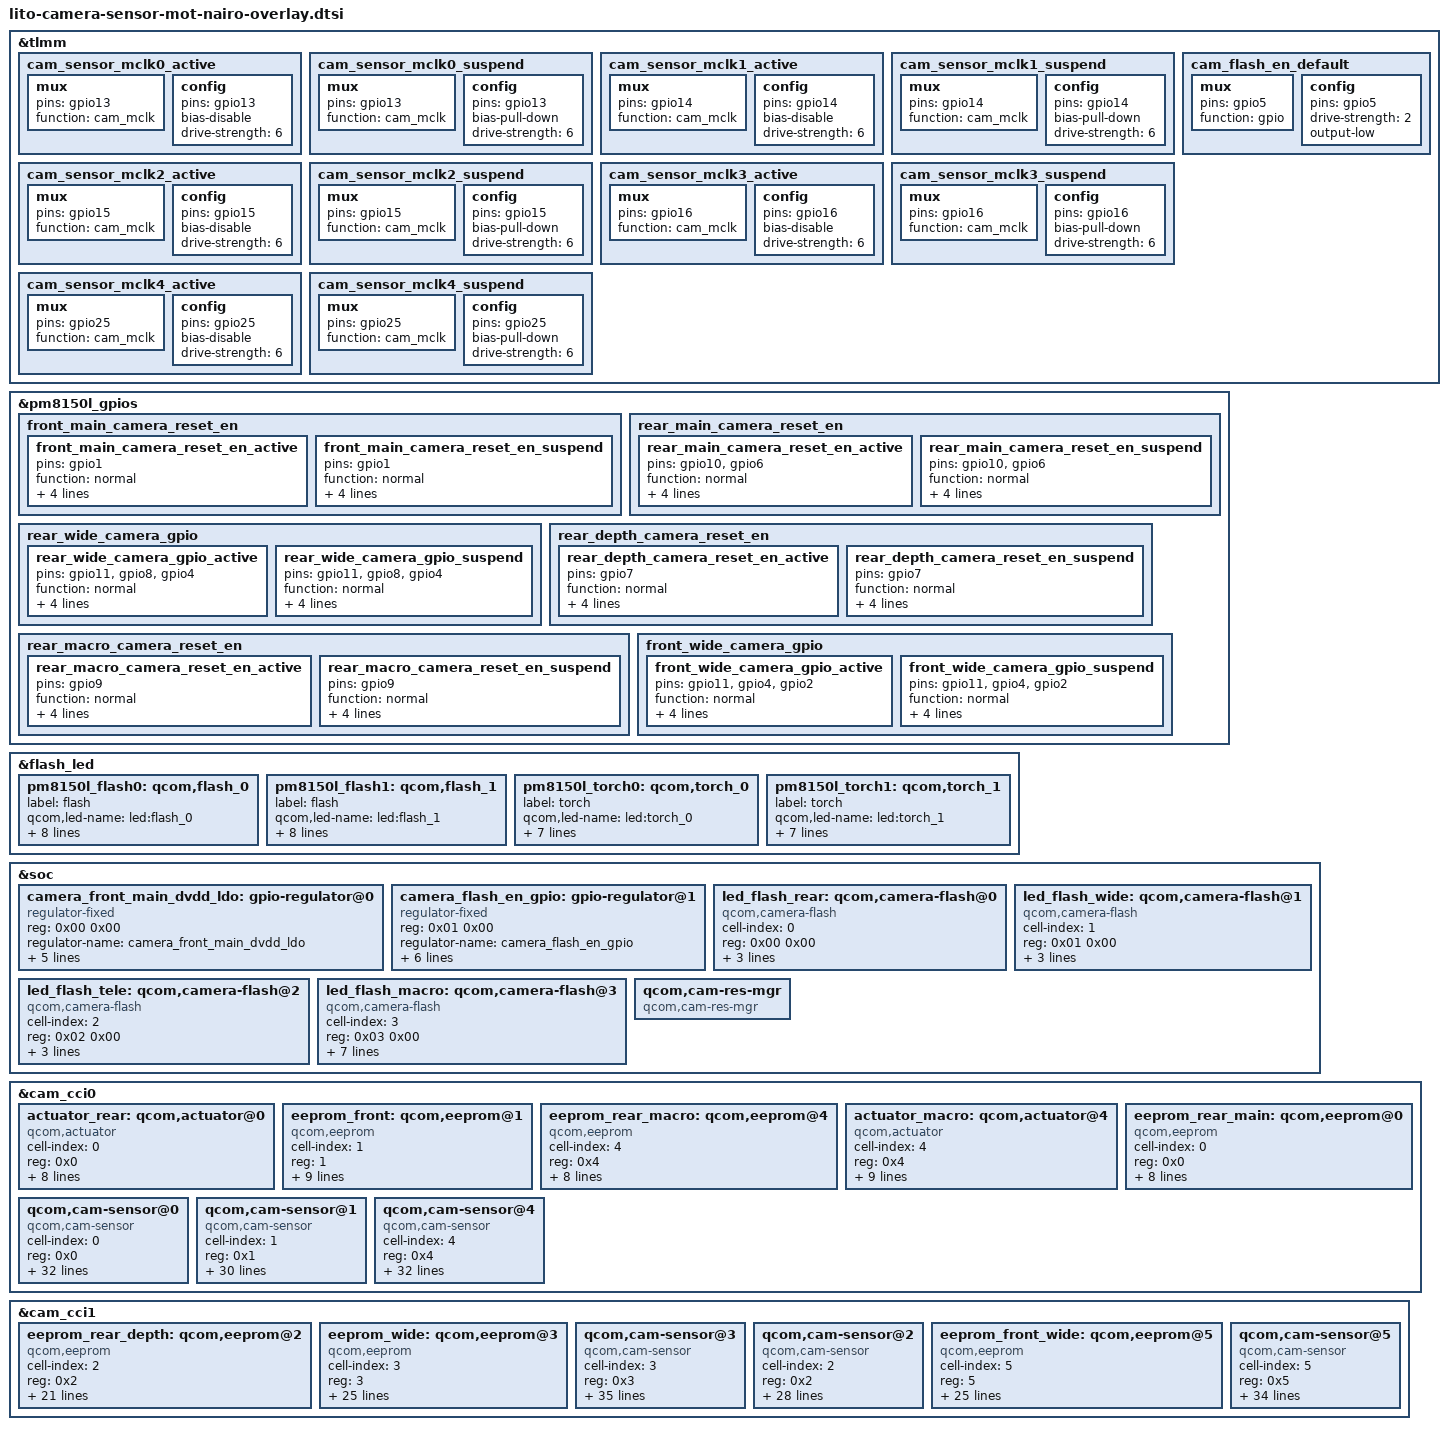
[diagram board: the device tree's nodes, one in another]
#include <dt-bindings/clock/qcom,camcc-lito.h>

&tlmm {
	cam_sensor_mclk0_active: cam_sensor_mclk0_active {
		/* MCLK0 */
		mux {
			pins = "gpio13";
			function = "cam_mclk";
		};

		config {
			pins = "gpio13";
			bias-disable; /* No PULL */
			drive-strength = <6>; /* 6 MA */
		};
	};

	cam_sensor_mclk0_suspend: cam_sensor_mclk0_suspend {
		/* MCLK0 */
		mux {
			pins = "gpio13";
			function = "cam_mclk";
		};

		config {
			pins = "gpio13";
			bias-pull-down; /* PULL DOWN */
			drive-strength = <6>; /* 6 MA */
		};
	};

	cam_sensor_mclk1_active: cam_sensor_mclk1_active {
		/* MCLK1 */
		mux {
			pins = "gpio14";
			function = "cam_mclk";
		};

		config {
			pins = "gpio14";
			bias-disable; /* No PULL */
			drive-strength = <6>; /* 6 MA */
		};
	};

	cam_sensor_mclk1_suspend: cam_sensor_mclk1_suspend {
		/* MCLK1 */
		mux {
			pins = "gpio14";
			function = "cam_mclk";
		};

		config {
			pins = "gpio14";
			bias-pull-down; /* PULL DOWN */
			drive-strength = <6>; /* 6 MA */
		};
	};

	cam_sensor_mclk2_active: cam_sensor_mclk2_active {
		/* MCLK2 */
		mux {
			pins = "gpio15";
			function = "cam_mclk";
		};

		config {
			pins = "gpio15";
			bias-disable; /* No PULL */
			drive-strength = <6>; /* 6 MA */
		};
	};

	cam_sensor_mclk2_suspend: cam_sensor_mclk2_suspend {
		/* MCLK2 */
		mux {
			pins = "gpio15";
			function = "cam_mclk";
		};

		config {
			pins = "gpio15";
			bias-pull-down; /* PULL DOWN */
			drive-strength = <6>; /* 6 MA */
		};
	};

	cam_sensor_mclk3_active: cam_sensor_mclk3_active {
		/* MCLK3 */
		mux {
			pins = "gpio16";
			function = "cam_mclk";
		};

		config {
			pins = "gpio16";
			bias-disable; /* No PULL */
			drive-strength = <6>; /* 6 MA */
		};
	};

	cam_sensor_mclk3_suspend: cam_sensor_mclk3_suspend {
		/* MCLK3 */
		mux {
			pins = "gpio16";
			function = "cam_mclk";
		};

		config {
			pins = "gpio16";
			bias-pull-down; /* PULL DOWN */
			drive-strength = <6>; /* 6 MA */
		};
	};

	cam_sensor_mclk4_active: cam_sensor_mclk4_active {
		/* MCLK4 */
		mux {
			pins = "gpio25";
			function = "cam_mclk";
		};

		config {
			pins = "gpio25";
			bias-disable; /* No PULL */
			drive-strength = <6>; /* 6 MA */
		};
	};

	cam_sensor_mclk4_suspend: cam_sensor_mclk4_suspend {
		/* MCLK4 */
		mux {
			pins = "gpio25";
			function = "cam_mclk";
		};

		config {
			pins = "gpio25";
			bias-pull-down; /* PULL DOWN */
			drive-strength = <6>; /* 6 MA */
		};
	};

	cam_flash_en_default: cam_flash_en_default {
		/* RESET */
		mux {
			pins = "gpio5";
			function = "gpio";
		};

		config{
			pins = "gpio5";
			drive-strength = <2>; /* 2 MA */
			output-low;
		};
	};
};
&pm8150l_gpios {
	front_main_camera_reset_en {
		front_main_camera_reset_en_active: front_main_camera_reset_en_active {
			pins = "gpio1";
			function = "normal";
			qcom,drive-strength = <2>;
			power-source = <0>;
			bias-disable;
			output-enable;
		};
		front_main_camera_reset_en_suspend: front_main_camera_reset_en_suspend {
			pins = "gpio1";
			function = "normal";
			qcom,drive-strength = <2>;
			power-source = <0>;
			bias-pull-down;
			output-low;
		};
	};
	/*       pmic gpio pins sequence：GPIO 7-11 in front, GPIO 1-6 in back    */
	rear_main_camera_reset_en {
		rear_main_camera_reset_en_active: rear_main_camera_reset_en_active {
			pins = "gpio10","gpio6";
			function = "normal";
			qcom,drive-strength = <2>;
			power-source = <1>;
			bias-disable;
			output-enable;
		};
		rear_main_camera_reset_en_suspend: rear_main_camera_reset_en_suspend {
			pins = "gpio10","gpio6";
			function = "normal";
			qcom,drive-strength = <2>;
			power-source = <1>;
			bias-pull-down;
			output-low;
		};
	};
	/*       pmic gpio pins sequence：GPIO 7-11 in front, GPIO 1-6 in back    */
	rear_wide_camera_gpio {
		rear_wide_camera_gpio_active: rear_wide_camera_gpio_active {
			pins = "gpio11","gpio8","gpio4";
			function = "normal";
			qcom,drive-strength = <2>;
			power-source = <1>;
			bias-disable;
			output-enable;
		};
		rear_wide_camera_gpio_suspend: rear_wide_camera_gpio_suspend {
			pins = "gpio11","gpio8","gpio4";
			function = "normal";
			qcom,drive-strength = <2>;
			power-source = <1>;
			bias-pull-down;
			output-low;
		};
	};

        rear_depth_camera_reset_en {
		rear_depth_camera_reset_en_active: rear_depth_camera_reset_en_active {
			pins = "gpio7";
			function = "normal";
			qcom,drive-strength = <2>;
                        power-source = <1>;
			bias-disable;
			output-enable;
			};
		rear_depth_camera_reset_en_suspend: rear_depth_camera_reset_en_suspend {
			pins = "gpio7";
			function = "normal";
			qcom,drive-strength = <2>;
			power-source = <1>;
			bias-pull-down;
			output-low;
		};
	};

	rear_macro_camera_reset_en {
		rear_macro_camera_reset_en_active: rear_macro_camera_reset_en_active {
			pins = "gpio9";
			function = "normal";
			qcom,drive-strength = <2>;
			power-source = <1>;
			bias-disable;
			output-enable;
			};
		rear_macro_camera_reset_en_suspend: rear_macro_camera_reset_en_suspend {
			pins = "gpio9";
			function = "normal";
			qcom,drive-strength = <2>;
			power-source = <1>;
			bias-pull-down;
			output-low;
		};
	};
	/*       pmic gpio pins sequence：GPIO 7-11 in front, GPIO 1-6 in back    */
	front_wide_camera_gpio {
		front_wide_camera_gpio_active: front_wide_camera_gpio_active {
			pins ="gpio11","gpio4","gpio2";
			function = "normal";
			qcom,drive-strength = <2>;
			power-source = <1>;
			bias-disable;
			output-enable;
		};
		front_wide_camera_gpio_suspend: front_wide_camera_gpio_suspend {
			pins ="gpio11","gpio4","gpio2";
			function = "normal";
			qcom,drive-strength = <2>;
			power-source = <1>;
			bias-pull-down;
			output-low;
		};
	};
};

&flash_led {
	pm8150l_flash0: qcom,flash_0 {
		label = "flash";
		qcom,led-name = "led:flash_0";
		qcom,max-current = <750>;
		qcom,default-led-trigger = "flash0_trigger";
		qcom,id = <0>;
		qcom,current-ma = <500>;
		qcom,duration-ms = <1280>;
		qcom,ires-ua = <12500>;
		qcom,hdrm-voltage-mv = <325>;
		qcom,hdrm-vol-hi-lo-win-mv = <100>;
	};

	pm8150l_flash1: qcom,flash_1 {
		label = "flash";
		qcom,led-name = "led:flash_1";
		qcom,max-current = <750>;
		qcom,default-led-trigger = "flash1_trigger";
		qcom,id = <1>;
		qcom,current-ma = <500>;
		qcom,duration-ms = <1280>;
		qcom,ires-ua = <12500>;
		qcom,hdrm-voltage-mv = <325>;
		qcom,hdrm-vol-hi-lo-win-mv = <100>;
	};

	pm8150l_torch0: qcom,torch_0 {
		label = "torch";
		qcom,led-name = "led:torch_0";
		qcom,max-current = <250>;
		qcom,default-led-trigger = "torch0_trigger";
		qcom,id = <0>;
		qcom,current-ma = <50>;
		qcom,ires-ua = <12500>;
		qcom,hdrm-voltage-mv = <325>;
		qcom,hdrm-vol-hi-lo-win-mv = <100>;
	};

	pm8150l_torch1: qcom,torch_1 {
		label = "torch";
		qcom,led-name = "led:torch_1";
		qcom,max-current = <250>;
		qcom,default-led-trigger = "torch1_trigger";
		qcom,id = <1>;
		qcom,current-ma = <50>;
		qcom,ires-ua = <12500>;
		qcom,hdrm-voltage-mv = <325>;
		qcom,hdrm-vol-hi-lo-win-mv = <100>;
	};
};

&soc {
	camera_front_main_dvdd_ldo: gpio-regulator@0 {
		compatible = "regulator-fixed";
		reg = <0x00 0x00>;
		regulator-name = "camera_front_main_dvdd_ldo";
		regulator-min-microvolt = <1200000>;
		regulator-max-microvolt = <1200000>;
		regulator-enable-ramp-delay = <135>;
		enable-active-high;
		gpio = <&pm8150l_gpios 10 0>;
	};

	camera_flash_en_gpio: gpio-regulator@1{
		compatible = "regulator-fixed";
		reg = <0x01 0x00>;
		regulator-name = "camera_flash_en_gpio";
		regulator-min-microvolt = <1800000>;
		regulator-max-microvolt = <1800000>;
		regulator-enable-ramp-delay = <233>;
		enable-active-high;
		gpio = <&tlmm 5 0>;
		pinctrl-names = "default";
		pinctrl-0 = <&cam_flash_en_default>;
	};

	led_flash_rear: qcom,camera-flash@0 {
		cell-index = <0>;
		reg = <0x00 0x00>;
		compatible = "qcom,camera-flash";
		flash-source = <&pm8150l_flash0 &pm8150l_flash1>;
		torch-source = <&pm8150l_torch0 &pm8150l_torch1>;
		switch-source = <&pm8150l_switch2>;
		status = "ok";
	};

	led_flash_wide: qcom,camera-flash@1 {
		cell-index = <1>;
		reg = <0x01 0x00>;
		compatible = "qcom,camera-flash";
		flash-source = <&pm8150l_flash0 &pm8150l_flash1>;
		torch-source = <&pm8150l_torch0 &pm8150l_torch1>;
		switch-source = <&pm8150l_switch2>;
		status = "ok";
	};

	led_flash_tele: qcom,camera-flash@2 {
		cell-index = <2>;
		reg = <0x02 0x00>;
		compatible = "qcom,camera-flash";
		flash-source = <&pm8150l_flash0 &pm8150l_flash1>;
		torch-source = <&pm8150l_torch0 &pm8150l_torch1>;
		switch-source = <&pm8150l_switch2>;
		status = "ok";
	};

	led_flash_macro: qcom,camera-flash@3 {
		cell-index = <3>;
		reg = <0x03 0x00>;
		compatible = "qcom,camera-flash";
		gpio-flash-support;
		cam_v_custom1-supply = <&camera_flash_en_gpio>;
		regulator-names = "cam_v_custom1";
		rgltr-cntrl-support;
		rgltr-min-voltage = <1800000>;
		rgltr-max-voltage = <1800000>;
		rgltr-load-current = <0>;
		status = "ok";
	};

	qcom,cam-res-mgr {
		compatible = "qcom,cam-res-mgr";
		status = "ok";
	};
};

&cam_cci0 {
	actuator_rear: qcom,actuator@0 {
		cell-index = <0>;
		reg = <0x0>;
		compatible = "qcom,actuator";
		cci-master = <0>;
		cam_vio-supply = <&cam_iovdd_ldo>;
		cam_vaf-supply = <&cam_main_macro_afvdd_ldo>;
		regulator-names = "cam_vio", "cam_vaf";
		rgltr-cntrl-support;
		rgltr-min-voltage = <1800000 2800000>;
		rgltr-max-voltage = <1800000 2800000>;
		rgltr-load-current = <0 100000>;
		status = "ok";
	};

	eeprom_front: qcom,eeprom@1 {
		cell-index = <1>;
		reg = <1>;
		compatible = "qcom,eeprom";
		cam_vio-supply = <&cam_iovdd_ldo>;
		regulator-names = "cam_vio";
		rgltr-cntrl-support;
		rgltr-min-voltage = <1800000>;
		rgltr-max-voltage = <1800000>;
		rgltr-load-current = <0>;
		sensor-mode = <1>;
		cci-device = <0>;
		cci-master = <1>;
		status = "ok";
	};

	eeprom_rear_macro: qcom,eeprom@4{
		cell-index = <4>;
		reg = <0x4>;
		compatible = "qcom,eeprom";
		cam_vio-supply = <&cam_iovdd_ldo>;
		regulator-names = "cam_vio";
		rgltr-cntrl-support;
		rgltr-min-voltage = <1800000>;
		rgltr-max-voltage = <1800000>;
		rgltr-load-current = <0>;
		cci-device = <0>;
		cci-master = <1>;
		status = "ok";
	};

	actuator_macro: qcom,actuator@4{
		cell-index = <4>;
		reg = <0x4>;
		compatible = "qcom,actuator";
		cci-device = <0>;
		cci-master = <1>;
		cam_vio-supply = <&cam_iovdd_ldo>;
		cam_vaf-supply = <&cam_main_macro_afvdd_ldo>;
		regulator-names = "cam_vio","cam_vaf";
		rgltr-cntrl-support;
		rgltr-min-voltage = <1800000 2800000>;
		rgltr-max-voltage = <1800000 2800000>;
		rgltr-load-current = <0 0>;
	};

	eeprom_rear_main: qcom,eeprom@0 {	//rear main GM1 eeprom
		cell-index = <0>;
		reg = <0x0>;
		compatible = "qcom,eeprom";
		cam_vaf-supply = <&cam_main_macro_afvdd_ldo>;
		cam_vio-supply = <&cam_iovdd_ldo>;
		regulator-names = "cam_vaf", "cam_vio";
		rgltr-cntrl-support;
		rgltr-min-voltage = <2800000 1800000>;
		rgltr-max-voltage = <2800000 1800000>;
		rgltr-load-current = <0 0>;
		cci-master = <0>;
		status = "ok";
	};

	qcom,cam-sensor@0 {	//rear main GM1
		cell-index = <0>;
		compatible = "qcom,cam-sensor";
		reg = <0x0>;
		csiphy-sd-index = <2>;
		sensor-position-roll = <90>;
		sensor-position-pitch = <0>;
		sensor-position-yaw = <180>;
		eeprom-src = <&eeprom_rear_main>;
		led-flash-src = <&led_flash_rear>;
		actuator-src = <&actuator_rear>;
		cam_vio-supply = <&cam_iovdd_ldo>;
		cam_vana-supply = <&cam_main_front_avdd_ldo>;
		cam_vdig-supply = <&cam_main_front_dvdd_ldo>;
		cam_clk-supply = <&titan_top_gdsc>;
		regulator-names = "cam_vio", "cam_vana", "cam_vdig",
			"cam_clk";
		rgltr-cntrl-support;
		rgltr-min-voltage = <1800000 2800000 1050000 0>;
		rgltr-max-voltage = <1800000 2800000 1050000 0>;
		rgltr-load-current = <0 80000 105000 0>;
		gpio-no-mux = <0>;
		pinctrl-names = "cam_default", "cam_suspend";
		pinctrl-0 = <&cam_sensor_mclk2_active
				&rear_main_camera_reset_en_active>;
		pinctrl-1 = <&cam_sensor_mclk2_suspend
				&rear_main_camera_reset_en_suspend>;
		gpios = <&tlmm 15 0>,
			<&pm8150l_gpios 6 0>;
		gpio-reset = <1>;
		gpio-req-tbl-num = <0 1>;
		gpio-req-tbl-flags = <1 0>;
		gpio-req-tbl-label = "CAMIF_MCLK2",
					"CAM_RESET2";
		cci-device = <0>;
		cci-master = <0>;
		status = "ok";
		clocks = <&camcc CAM_CC_MCLK2_CLK>;
		clock-names = "cam_clk";
		clock-cntl-level = "turbo";
		clock-rates = <24000000>;
	};

	qcom,cam-sensor@1 {    //front main ov16a1q
		cell-index = <1>;
		compatible = "qcom,cam-sensor";
		reg = <0x1>;
		csiphy-sd-index = <1>;
		sensor-position-roll = <90>;
		sensor-position-pitch = <0>;
		sensor-position-yaw = <180>;
		eeprom-src = <&eeprom_front>;
		cam_vio-supply = <&cam_iovdd_ldo>;
		cam_vana-supply = <&cam_main_front_avdd_ldo>;
		cam_vdig-supply = <&camera_front_main_dvdd_ldo>;
		cam_clk-supply = <&titan_top_gdsc>;
		regulator-names = "cam_vio", "cam_vana", "cam_vdig",
			"cam_clk";
		rgltr-cntrl-support;
		rgltr-min-voltage = <1800000 2800000 1200000 0>;
		rgltr-max-voltage = <1800000 2800000 1200000 0>;
		rgltr-load-current = <0 80000 105000 0>;
		gpio-no-mux = <0>;
		pinctrl-names = "cam_default", "cam_suspend";
		pinctrl-0 = <&cam_sensor_mclk1_active
				&front_main_camera_reset_en_active>;
		pinctrl-1 = <&cam_sensor_mclk1_suspend
				&front_main_camera_reset_en_suspend>;
		gpios = <&tlmm 14 0>,
			<&pm8150l_gpios 1 0>;
		gpio-reset = <1>;
		gpio-req-tbl-num = <0 1>;
		gpio-req-tbl-flags = <1 0>;
		gpio-req-tbl-label = "CAMIF_MCLK1",
					"CAM_RESET1";
		cci-device = <0>;
		cci-master = <1>;
		status = "ok";
		clocks = <&camcc CAM_CC_MCLK1_CLK>;
		clock-names = "cam_clk";
		clock-cntl-level = "turbo";
		clock-rates = <24000000>;
	};

	qcom,cam-sensor@4{    //s5k5e9
		cell-index = <4>;
		compatible = "qcom,cam-sensor";
		reg = <0x4>;
		csiphy-sd-index = <3>;
		sensor-position-roll = <90>;
		sensor-position-pitch = <0>;
		sensor-position-yaw = <180>;
		eeprom-src = <&eeprom_rear_macro>;
		actuator-src = <&actuator_macro>;
		led-flash-src = <&led_flash_macro>;
		cam_vio-supply = <&cam_iovdd_ldo>;
		cam_vana-supply = <&cam_wide_depth_macro_avdd_ldo>;
		cam_vdig-supply = <&cam_wide_macro_dvdd_ldo>;
		cam_clk-supply = <&titan_top_gdsc>;
		regulator-names = "cam_vio", "cam_vana", "cam_vdig",
			"cam_clk";
		rgltr-cntrl-support;
		rgltr-min-voltage = <1800000 2800000 1200000 0>;
		rgltr-max-voltage = <1800000 2800000 1200000 0>;
		rgltr-load-current = <0 80000 105000 0>;
		gpio-no-mux = <0>;
		pinctrl-names = "cam_default", "cam_suspend";
		pinctrl-0 = <&cam_sensor_mclk3_active
				&rear_macro_camera_reset_en_active>;
		pinctrl-1 = <&cam_sensor_mclk3_suspend
				&rear_macro_camera_reset_en_suspend>;
		gpios = <&tlmm 16 0>,
			<&pm8150l_gpios 9 0>;
		gpio-reset = <1>;
		gpio-req-tbl-num = <0 1>;
		gpio-req-tbl-flags = <1 0>;
		gpio-req-tbl-label = "CAMIF_MCLK3",
					"CAM_RESET3";
		cci-device = <0>;
		cci-master = <1>;
		status = "ok";
		clocks = <&camcc CAM_CC_MCLK3_CLK>;
		clock-names = "cam_clk";
		clock-cntl-level = "turbo";
		clock-rates = <24000000>;
	};
};

&cam_cci1 {

	eeprom_rear_depth: qcom,eeprom@2{
		cell-index = <2>;
		reg = <0x2>;
		compatible = "qcom,eeprom";
		cam_vio-supply = <&cam_iovdd_ldo>;
		cam_vana-supply = <&cam_wide_depth_macro_avdd_ldo>;
		cam_clk-supply = <&titan_top_gdsc>;
		regulator-names = "cam_vio", "cam_vana", "cam_clk";
		rgltr-cntrl-support;
		rgltr-min-voltage = <1800000 2800000 0>;
		rgltr-max-voltage = <1800000 2800000 0>;
		rgltr-load-current = <0 80000 0>;
		gpio-no-mux = <0>;
		pinctrl-names = "cam_default", "cam_suspend";
		pinctrl-0 = <&cam_sensor_mclk3_active>;
		pinctrl-1 = <&cam_sensor_mclk3_suspend>;
		gpios = <&tlmm 16 0>,
			<&pm8150l_gpios 7 0>;
		gpio-reset = <1>;
		gpio-req-tbl-num = <0 1>;
		gpio-req-tbl-flags = <1 0>;
		gpio-req-tbl-label = "CAMIF_MCLK3",
					"CAM_RESET4";
		cci-device = <1>;
		cci-master = <0>;
		status = "ok";
		clocks = <&camcc CAM_CC_MCLK3_CLK>;
		clock-names = "cam_clk";
		clock-cntl-level = "turbo";
		clock-rates = <24000000>;
	};

	eeprom_wide: qcom,eeprom@3 {	//rear wide:4h7 eeprom
		cell-index = <3>;
		reg = <3>;
		compatible = "qcom,eeprom";
		cam_vio-supply = <&cam_iovdd_ldo>;
		cam_vana-supply = <&cam_wide_depth_macro_avdd_ldo>;
		cam_vdig-supply = <&cam_wide_macro_dvdd_ldo>;
		cam_clk-supply = <&titan_top_gdsc>;
		regulator-names = "cam_vio", "cam_vana", "cam_vdig",
			"cam_clk";
		rgltr-cntrl-support;
		rgltr-min-voltage = <1800000 2800000 1200000 0>;
		rgltr-max-voltage = <1800000 2800000 1200000 0>;
		rgltr-load-current = <0 80000 105000 0>;
		gpio-no-mux = <0>;
		pinctrl-names = "cam_default", "cam_suspend";
		pinctrl-0 = <&cam_sensor_mclk4_active
				&rear_wide_camera_gpio_active>;
		pinctrl-1 = <&cam_sensor_mclk4_suspend
				&rear_wide_camera_gpio_suspend>;
		gpios = <&tlmm 25 0>,
			<&pm8150l_gpios 8 0>;
		gpio-reset = <1>;
		gpio-req-tbl-num = <0 1>;
		gpio-req-tbl-flags = <1 0>;
		gpio-req-tbl-label = "CAMIF_MCLK4",
					"CAM_RESET4";
		cci-device = <1>;
		cci-master = <0>;
		status = "ok";
		clocks = <&camcc CAM_CC_MCLK4_CLK>;
		clock-names = "cam_clk";
		clock-cntl-level = "turbo";
		clock-rates = <24000000>;
	};

	qcom,cam-sensor@3 {	//rear wide:4h7
		cell-index = <3>;
		compatible = "qcom,cam-sensor";
		reg = <0x3>;
		csiphy-sd-index = <0>;
		sensor-position-roll = <90>;
		sensor-position-pitch = <0>;
		sensor-position-yaw = <180>;
		eeprom-src = <&eeprom_wide>;
		led-flash-src = <&led_flash_wide>;
		cam_vio-supply = <&cam_iovdd_ldo>;
		cam_vana-supply = <&cam_wide_depth_macro_avdd_ldo>;
		cam_vdig-supply = <&cam_wide_macro_dvdd_ldo>;
		cam_clk-supply = <&titan_top_gdsc>;
		regulator-names = "cam_vio", "cam_vana", "cam_vdig",
			"cam_clk";
		rgltr-cntrl-support;
		rgltr-min-voltage = <1800000 2800000 1200000 0>;
		rgltr-max-voltage = <1800000 2800000 1200000 0>;
		rgltr-load-current = <0 80000 105000 0>;
		gpio-no-mux = <0>;
		pinctrl-names = "cam_default", "cam_suspend";
		pinctrl-0 = <&cam_sensor_mclk4_active
				&rear_wide_camera_gpio_active>;
		pinctrl-1 = <&cam_sensor_mclk4_suspend
				&rear_wide_camera_gpio_suspend>;
		gpios = <&tlmm 25 0>,
			<&pm8150l_gpios 8 0>,
			<&pm8150l_gpios 4 0>,
			<&pm8150l_gpios 11 0>;
		gpio-reset = <1>;
		gpio-custom1 = <2>;
		gpio-custom2 = <3>;
		gpio-req-tbl-num = <0 1 2 3>;
		gpio-req-tbl-flags = <1 0 0 0>;
		gpio-req-tbl-label = "CAMIF_MCLK4",
					"CAM_RESET4",
					"CAM_MIPI_EN",
					"CAM_MIPI_SEL";
		cci-device = <1>;
		cci-master = <0>;
		status = "ok";
		clocks = <&camcc CAM_CC_MCLK4_CLK>;
		clock-names = "cam_clk";
		clock-cntl-level = "turbo";
		clock-rates = <24000000>;
	};

	qcom,cam-sensor@2{                       //ov2180
		cell-index = <2>;
		compatible = "qcom,cam-sensor";
		reg = <0x2>;
		csiphy-sd-index = <3>;
		sensor-position-roll = <90>;
		sensor-position-pitch = <0>;
		sensor-position-yaw = <180>;
		eeprom-src = <&eeprom_rear_depth>;
		cam_vio-supply = <&cam_iovdd_ldo>;
		cam_vana-supply = <&cam_wide_depth_macro_avdd_ldo>;
		cam_clk-supply = <&titan_top_gdsc>;
		regulator-names = "cam_vio", "cam_vana", "cam_clk";
		rgltr-cntrl-support;
		rgltr-min-voltage = <1800000 2800000 0>;
		rgltr-max-voltage = <1800000 2800000 0>;
		rgltr-load-current = <0 80000 0>;
		gpio-no-mux = <0>;
		pinctrl-names = "cam_default", "cam_suspend";
		pinctrl-0 = <&cam_sensor_mclk3_active
				&rear_depth_camera_reset_en_active>;
		pinctrl-1 = <&cam_sensor_mclk3_suspend
				&rear_depth_camera_reset_en_suspend>;
		gpios = <&tlmm 16 0>,
			<&pm8150l_gpios 7 0>;
		gpio-reset = <1>;
		gpio-req-tbl-num = <0 1>;
		gpio-req-tbl-flags = <1 0>;
		gpio-req-tbl-label = "CAMIF_MCLK3",
					"CAM_RESET4";
		cci-device = <1>;
		cci-master = <0>;
		status = "ok";
		clocks = <&camcc CAM_CC_MCLK3_CLK>;
		clock-names = "cam_clk";
		clock-cntl-level = "turbo";
		clock-rates = <24000000>;
	};

	eeprom_front_wide: qcom,eeprom@5 {	//front wide:4h7 eeprom
		cell-index = <5>;
		reg = <5>;
		compatible = "qcom,eeprom";
		cam_vio-supply = <&cam_iovdd_ldo>;
		cam_vana-supply = <&cam_main_front_avdd_ldo>;
		cam_vdig-supply = <&cam_wide_macro_dvdd_ldo>;
		cam_clk-supply = <&titan_top_gdsc>;
		regulator-names = "cam_vio", "cam_vana", "cam_vdig",
			"cam_clk";
		rgltr-cntrl-support;
		rgltr-min-voltage = <1800000 2800000 1200000 0>;
		rgltr-max-voltage = <1800000 2800000 1200000 0>;
		rgltr-load-current = <0 80000 105000 0>;
		gpio-no-mux = <0>;
		pinctrl-names = "cam_default", "cam_suspend";
		pinctrl-0 = <&cam_sensor_mclk0_active
				&front_wide_camera_gpio_active>;
		pinctrl-1 = <&cam_sensor_mclk0_suspend
				&front_wide_camera_gpio_suspend>;
		gpios = <&tlmm 13 0>,
			<&pm8150l_gpios 2 0>;
		gpio-reset = <1>;
		gpio-req-tbl-num = <0 1>;
		gpio-req-tbl-flags = <1 0>;
		gpio-req-tbl-label = "CAMIF_MCLK0",
					"CAM_RESET0";
		cci-device = <1>;
		cci-master = <0>;
		status = "ok";
		clocks = <&camcc CAM_CC_MCLK0_CLK>;
		clock-names = "cam_clk";
		clock-cntl-level = "turbo";
		clock-rates = <24000000>;
	};

	qcom,cam-sensor@5 {	//front wide 4h7
		cell-index = <5>;
		compatible = "qcom,cam-sensor";
		reg = <0x5>;
		csiphy-sd-index = <0>;
		sensor-position-roll = <270>;
		sensor-position-pitch = <0>;
		sensor-position-yaw = <0>;
		eeprom-src = <&eeprom_front_wide>;
		cam_vio-supply = <&cam_iovdd_ldo>;
		cam_vana-supply = <&cam_main_front_avdd_ldo>;
		cam_vdig-supply = <&cam_wide_macro_dvdd_ldo>;
		cam_clk-supply = <&titan_top_gdsc>;
		regulator-names = "cam_vio", "cam_vana", "cam_vdig",
			"cam_clk";
		rgltr-cntrl-support;
		rgltr-min-voltage = <1800000 2800000 1200000 0>;
		rgltr-max-voltage = <1800000 2800000 1200000 0>;
		rgltr-load-current = <0 80000 105000 0>;
		gpio-no-mux = <0>;
		pinctrl-names = "cam_default", "cam_suspend";
		pinctrl-0 = <&cam_sensor_mclk0_active
				&front_wide_camera_gpio_active>;
		pinctrl-1 = <&cam_sensor_mclk0_suspend
				&front_wide_camera_gpio_suspend>;
		gpios = <&tlmm 13 0>,
			<&pm8150l_gpios 2 0>,
			<&pm8150l_gpios 4 0>,
			<&pm8150l_gpios 11 0>;
		gpio-reset = <1>;
		gpio-custom1 = <2>;
		gpio-custom2 = <3>;
		gpio-req-tbl-num = <0 1 2 3>;
		gpio-req-tbl-flags = <1 0 0 0>;
		gpio-req-tbl-label = "CAMIF_MCLK0",
					"CAM_RESET0",
					"CAM_MIPI_EN",
					"CAM_MIPI_SEL";
		cci-device = <1>;
		cci-master = <0>;
		status = "ok";
		clocks = <&camcc CAM_CC_MCLK0_CLK>;
		clock-names = "cam_clk";
		clock-cntl-level = "turbo";
		clock-rates = <24000000>;
	};

};

